# TM4C1294NCPDT register map
Vendor: Texas Instruments; File version: 2.2.0.295
CPU: CM4 r0p1, little endian, MPU, FPU, 3 interrupt priority bits
Registers are 32-bit, read-write, no defined reset value unless marked. A register's access mark holds for its fields unless they carry their own. Offsets are from the block's base; [hi:lo] are bit positions; {n}, {i} and the like mark numbered series; 'fields as' and 'values as' point back to an identical list.

## ADC0 — ADC (ADC0)
Base 0x40038000
Same registers: ADC1 0x40039000
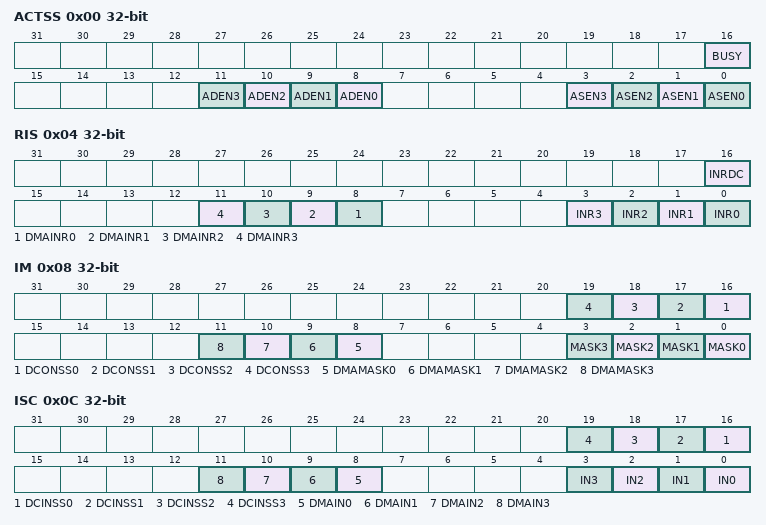
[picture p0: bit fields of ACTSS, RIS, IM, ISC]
0x00 ACTSS
  [16] BUSY — ADC Busy
  [11] ADEN3 — ADC SS3 DMA Enable
  [10] ADEN2 — ADC SS2 DMA Enable
  [9] ADEN1 — ADC SS1 DMA Enable
  [8] ADEN0 — ADC SS1 DMA Enable
  [n] ASEN{n} (n=0..3) — ADC SS{n} Enable
0x04 RIS
  [16] INRDC — Digital Comparator Raw Interrupt
  [n+8] DMAINR{n} (n=0..3) — SS{n} DMA Raw Interrupt Status
  [n] INR{n} (n=0..3) — SS{n} Raw Interrupt Status
0x08 IM
  [n+16] DCONSS{n} (n=0..3) — Digital Comparator Interrupt on
  [n+8] DMAMASK{n} (n=0..3) — SS{n} DMA Interrupt Mask
  [n] MASK{n} (n=0..3) — SS{n} Interrupt Mask
0x0C ISC
  [n+16] DCINSS{n} (n=0..3) — Digital Comparator Interrupt
  [n+8] DMAIN{n} (n=0..3) — SS{n} DMA Interrupt Status and
  [n] IN{n} (n=0..3) — SS{n} Interrupt Status and Clear
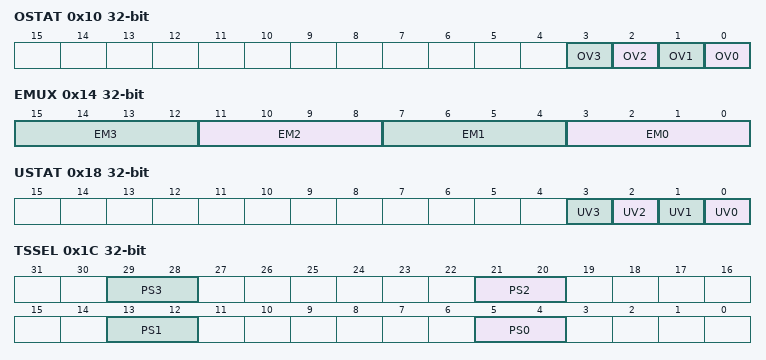
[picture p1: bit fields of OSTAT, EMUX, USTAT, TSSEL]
0x10 OSTAT
  [n] OV{n} (n=0..3) — SS{n} FIFO Overflow
0x14 EMUX
  [all] fields
    0=PROCESSOR (Processor (default)); 1=COMP0 (Analog Comparator 0); 2=COMP1 (Analog Comparator 1); 3=COMP2 (Analog Comparator 2); 4=EXTERNAL (External (GPIO Pins)); 5=TIMER; {v}=PWM{v-6} (PWM generator {v-6}) (v=6..9); 14=NEVER (Never Trigger); 15=ALWAYS (Always (continuously sample))
  [4n+3:4n] EM{n} (n=0..3) — SS{n} Trigger Select
0x18 USTAT
  [n] UV{n} (n=0..3) — SS{n} FIFO Underflow
0x1C TSSEL
  [8n+5:8n+4] PS{n} (n=0..3) — Generator {n} PWM Module Trigger
    0=Use Generator {n} (and its
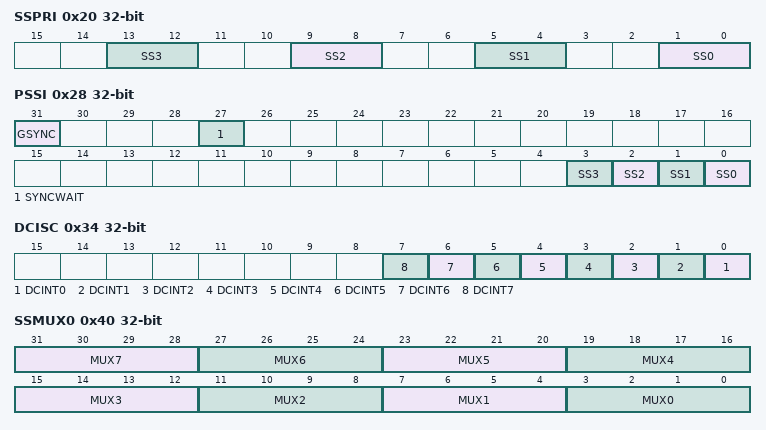
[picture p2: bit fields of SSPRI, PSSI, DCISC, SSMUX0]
0x20 SSPRI
  [4n+1:4n] SS{n} (n=0..3) — SS{n} Priority
0x24 SPC
  [3:0] PHASE — Phase Difference
    0=ADC sample lags by 0.0; 1=22_5 (ADC sample lags by 22.5); 2=ADC sample lags by 45.0; 3=67_5 (ADC sample lags by 67.5); 4=ADC sample lags by 90.0; 5=112_5 (ADC sample lags by 112.5); 6=ADC sample lags by 135.0; 7=157_5 (ADC sample lags by 157.5); 8=ADC sample lags by 180.0; 9=202_5 (ADC sample lags by 202.5); 10=ADC sample lags by 225.0; 11=247_5 (ADC sample lags by 247.5); 12=ADC sample lags by 270.0; 13=292_5 (ADC sample lags by 292.5); 14=ADC sample lags by 315.0; 15=337_5 (ADC sample lags by 337.5)
0x28 PSSI
  [31] GSYNC — Global Synchronize
  [27] SYNCWAIT — Synchronize Wait
  [n] SS{n} (n=0..3) — SS{n} Initiate
0x30 SAC
  [2:0] AVG — Hardware Averaging Control
    0=OFF (No hardware oversampling); 1=2X (2x hardware oversampling); 2=4X (4x hardware oversampling); 3=8X (8x hardware oversampling); 4=16X (16x hardware oversampling); 5=32X (32x hardware oversampling); 6=64X (64x hardware oversampling)
0x34 DCISC
  [n] DCINT{n} (n=0..7) — Digital Comparator {n} Interrupt
0x38 CTL
  [0] VREF — Voltage Reference Select
  [0] VREF_EXT_3V — The external VREFA+ and VREFA-
0x40 SSMUX0
  [4n+3:4n] MUX{n} (n=3..7) — {n+1}th Sample Input Select
  [11:8] MUX2 — 3rd Sample Input Select
  [7:4] MUX1 — 2nd Sample Input Select
  [3:0] MUX0 — 1st Sample Input Select
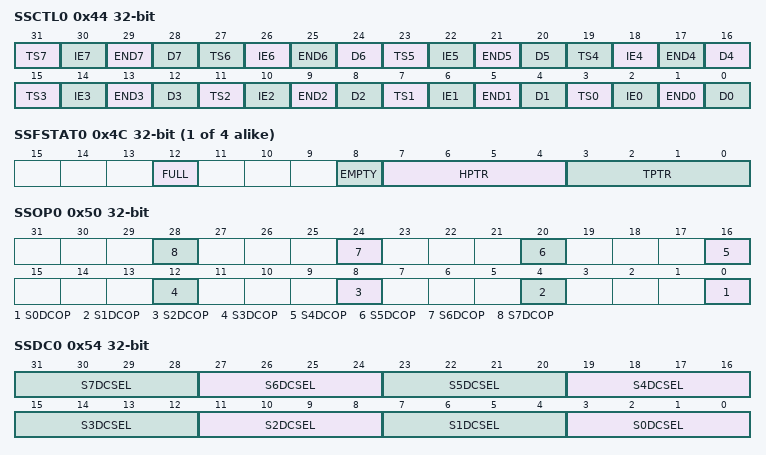
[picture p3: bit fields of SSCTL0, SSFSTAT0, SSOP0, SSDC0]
0x44 SSCTL0
  [4n+3] TS{n} (n=3..7) — {n+1}th Sample Temp Sensor Select
  [4n+2] IE{n} (n=3..7) — {n+1}th Sample Interrupt Enable
  [4n+1] END{n} (n=3..7) — {n+1}th Sample is End of Sequence
  [4n] D{n} (n=3..7) — {n+1}th Sample Differential Input
  [11] TS2 — 3rd Sample Temp Sensor Select
  [10] IE2 — 3rd Sample Interrupt Enable
  [9] END2 — 3rd Sample is End of Sequence
  [8] D2 — 3rd Sample Differential Input
  [7] TS1 — 2nd Sample Temp Sensor Select
  [6] IE1 — 2nd Sample Interrupt Enable
  [5] END1 — 2nd Sample is End of Sequence
  [4] D1 — 2nd Sample Differential Input
  [3] TS0 — 1st Sample Temp Sensor Select
  [2] IE0 — 1st Sample Interrupt Enable
  [1] END0 — 1st Sample is End of Sequence
  [0] D0 — 1st Sample Differential Input
{0x48+0x20*i} SSFIFO{i} read-modifies (i=0..3)
  [11:0] DATA — Conversion Result Data
{0x4C+0x20*i} SSFSTAT{i} (i=0..3)
  [12] FULL — FIFO Full
  [8] EMPTY — FIFO Empty
  [7:4] HPTR — FIFO Head Pointer
  [3:0] TPTR — FIFO Tail Pointer
0x50 SSOP0
  [4n] S{n}DCOP (n=0..7) — Sample {n} Digital Comparator
0x54 SSDC0
  [4n+3:4n] S{n}DCSEL (n=0..7) — Sample {n} Digital Comparator
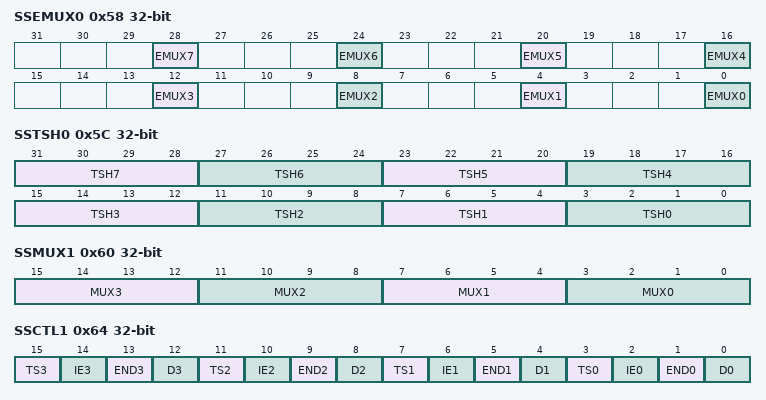
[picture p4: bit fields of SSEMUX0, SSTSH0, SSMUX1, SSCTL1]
0x58 SSEMUX0
  [4n] EMUX{n} (n=3..7) — {n+1}th Sample Input Select (Upper
  [8] EMUX2 — 3rd Sample Input Select (Upper
  [4] EMUX1 — 2th Sample Input Select (Upper
  [0] EMUX0 — 1st Sample Input Select (Upper
0x5C SSTSH0
  [4n+3:4n] TSH{n} (n=3..7) — {n+1}th Sample and Hold Period
  [11:8] TSH2 — 3rd Sample and Hold Period
  [7:4] TSH1 — 2nd Sample and Hold Period
  [3:0] TSH0 — 1st Sample and Hold Period
0x60 SSMUX1
  [15:12] MUX3 — 4th Sample Input Select
  [11:8] MUX2 — 3rd Sample Input Select
  [7:4] MUX1 — 2nd Sample Input Select
  [3:0] MUX0 — 1st Sample Input Select
0x64 SSCTL1
  [15] TS3 — 4th Sample Temp Sensor Select
  [14] IE3 — 4th Sample Interrupt Enable
  [13] END3 — 4th Sample is End of Sequence
  [12] D3 — 4th Sample Differential Input
  [11] TS2 — 3rd Sample Temp Sensor Select
  [10] IE2 — 3rd Sample Interrupt Enable
  [9] END2 — 3rd Sample is End of Sequence
  [8] D2 — 3rd Sample Differential Input
  [7] TS1 — 2nd Sample Temp Sensor Select
  [6] IE1 — 2nd Sample Interrupt Enable
  [5] END1 — 2nd Sample is End of Sequence
  [4] D1 — 2nd Sample Differential Input
  [3] TS0 — 1st Sample Temp Sensor Select
  [2] IE0 — 1st Sample Interrupt Enable
  [1] END0 — 1st Sample is End of Sequence
  [0] D0 — 1st Sample Differential Input
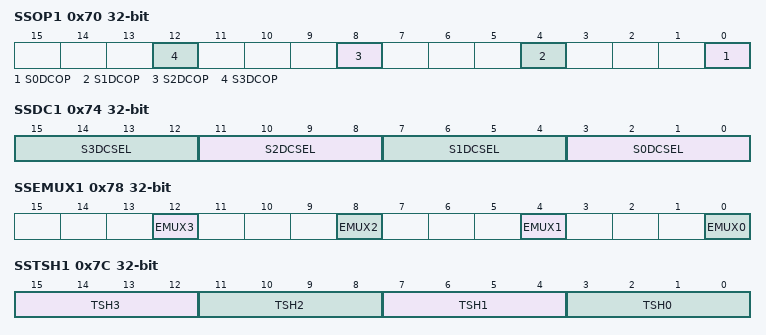
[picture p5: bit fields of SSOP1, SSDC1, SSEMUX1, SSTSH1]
0x70 SSOP1
  [4n] S{n}DCOP (n=0..3) — Sample {n} Digital Comparator
0x74 SSDC1
  [4n+3:4n] S{n}DCSEL (n=0..3) — Sample {n} Digital Comparator
0x78 SSEMUX1
  [12] EMUX3 — 4th Sample Input Select (Upper
  [8] EMUX2 — 3rd Sample Input Select (Upper
  [4] EMUX1 — 2th Sample Input Select (Upper
  [0] EMUX0 — 1st Sample Input Select (Upper
0x7C SSTSH1
  [15:12] TSH3 — 4th Sample and Hold Period
  [11:8] TSH2 — 3rd Sample and Hold Period
  [7:4] TSH1 — 2nd Sample and Hold Period
  [3:0] TSH0 — 1st Sample and Hold Period
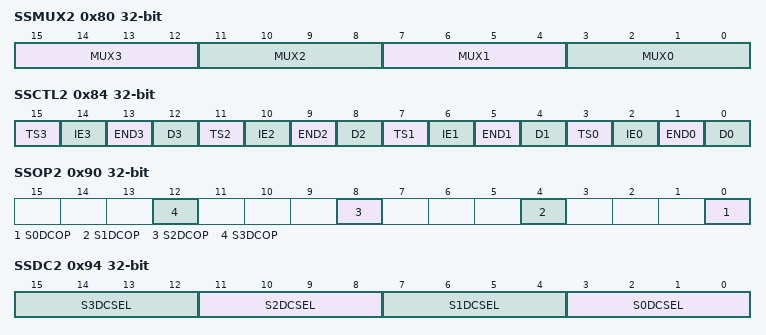
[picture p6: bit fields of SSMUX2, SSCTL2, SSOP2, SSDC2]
0x80 SSMUX2
  fields as SSMUX1
0x84 SSCTL2
  fields as SSCTL1
0x90 SSOP2
  [4n] S{n}DCOP (n=0..3) — Sample {n} Digital Comparator
0x94 SSDC2
  [4n+3:4n] S{n}DCSEL (n=0..3) — Sample {n} Digital Comparator
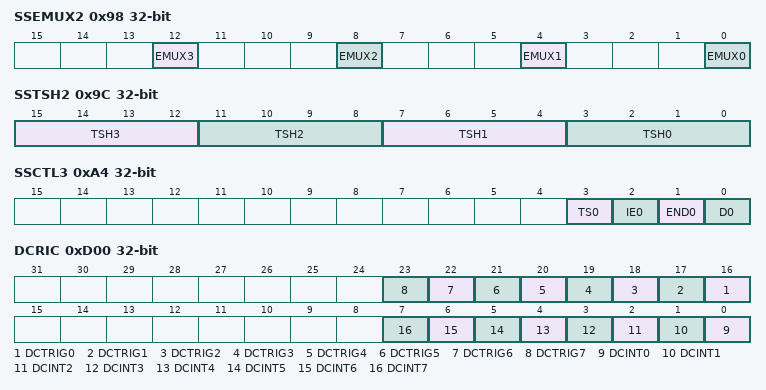
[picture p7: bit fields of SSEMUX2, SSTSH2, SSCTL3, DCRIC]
0x98 SSEMUX2
  fields as SSEMUX1
0x9C SSTSH2
  fields as SSTSH1
0xA0 SSMUX3
  [3:0] MUX0 — 1st Sample Input Select
0xA4 SSCTL3
  [3] TS0 — 1st Sample Temp Sensor Select
  [2] IE0 — Sample Interrupt Enable
  [1] END0 — End of Sequence
  [0] D0 — Sample Differential Input Select
0xB0 SSOP3
  [0] S0DCOP — Sample 0 Digital Comparator
0xB4 SSDC3
  [3:0] S0DCSEL — Sample 0 Digital Comparator
0xB8 SSEMUX3
  [0] EMUX0 — 1st Sample Input Select (Upper
0xBC SSTSH3
  [3:0] TSH0 — 1st Sample and Hold Period
0xD00 DCRIC
  [n+16] DCTRIG{n} (n=0..7) — Digital Comparator Trigger {n}
  [n] DCINT{n} (n=0..7) — Digital Comparator Interrupt {n}
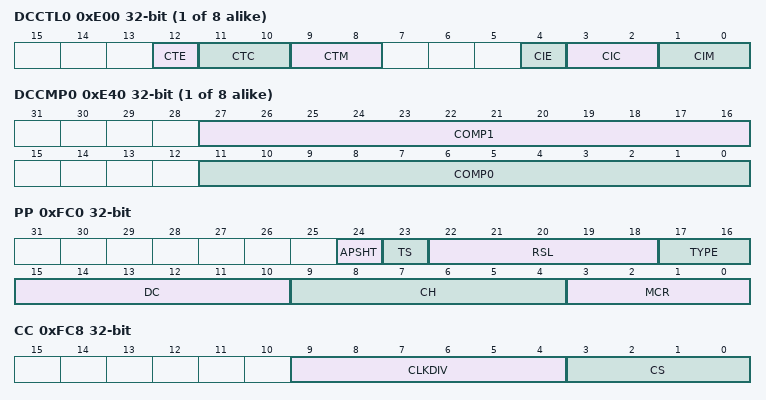
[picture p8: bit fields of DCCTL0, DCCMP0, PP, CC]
{0xE00+4i} DCCTL{i} (i=0..7)
  [12] CTE — Comparison Trigger Enable
  [11:10] CTC — Comparison Trigger Condition
    0=LOW (Low Band); 1=MID (Mid Band); 3=HIGH (High Band)
  [9:8] CTM — Comparison Trigger Mode
    0=ALWAYS; 1=ONCE; 2=HALWAYS (Hysteresis Always); 3=HONCE (Hysteresis Once)
  [4] CIE — Comparison Interrupt Enable
  [3:2] CIC — Comparison Interrupt Condition
    0=LOW (Low Band); 1=MID (Mid Band); 3=HIGH (High Band)
  [1:0] CIM — Comparison Interrupt Mode
    values as CTM
{0xE40+4i} DCCMP{i} (i=0..7)
  [27:16] COMP1 — Compare 1
  [11:0] COMP0 — Compare 0
0xFC0 PP
  [24] APSHT — Application-Programmable
  [23] TS — Temperature Sensor
  [22:18] RSL — Resolution
  [17:16] TYPE — ADC Architecture
    0=SAR
  [15:10] DC — Digital Comparator Count
  [9:4] CH — ADC Channel Count
  [3:0] MCR — Maximum Conversion Rate
    7=FULL (Full conversion rate (FCONV) as)
0xFC4 PC
  [3:0] MCR — Conversion Rate
    1=1_8 (Eighth conversion rate. After a); 3=1_4 (Quarter conversion rate. After a); 5=1_2 (Half conversion rate. After a); 7=FULL (Full conversion rate (FCONV) as)
0xFC8 CC
  [9:4] CLKDIV — PLL VCO Clock Divisor
  [3:0] CS — ADC Clock Source
    0=SYSPLL (PLL VCO divided by CLKDIV); 1=PIOSC; 2=MOSC
